VERSION "created by canmatrix"

NS_ :

BS_:

BU_: User ADB_PC_AC01 ADB_PC_BASE ADB_PC_BOX

BO_ 2155937856 AC01_Mode_Set: 1 User
 SG_ mode : 0|8@1+ (1,0) [0|255] "" ADB_PC_AC01,User

BO_ 2155937857 AC01_Mode_Applied: 1 ADB_PC_AC01
 SG_ mode : 0|8@1+ (1,0) [0|255] "" User

BO_ 2155937858 AC01_faults: 8 ADB_PC_AC01
 SG_ CABLE_1_2_L1 : 0|1@1+ (1,0) [0|1] "" User
 SG_ CABLE_1_3_L1 : 1|1@1+ (1,0) [0|1] "" User
 SG_ CABLE_1_2_L2 : 2|1@1+ (1,0) [0|1] "" User
 SG_ CABLE_1_3_L2 : 3|1@1+ (1,0) [0|1] "" User
 SG_ CABLE_1_2_L3 : 4|1@1+ (1,0) [0|1] "" User
 SG_ CABLE_1_3_L3 : 5|1@1+ (1,0) [0|1] "" User
 SG_ CABLE_4_5_L1 : 6|1@1+ (1,0) [0|1] "" User
 SG_ CABLE_4_6_L1 : 7|1@1+ (1,0) [0|1] "" User
 SG_ CABLE_4_5_L2 : 8|1@1+ (1,0) [0|1] "" User
 SG_ CABLE_4_6_L2 : 9|1@1+ (1,0) [0|1] "" User
 SG_ CABLE_4_5_L3 : 10|1@1+ (1,0) [0|1] "" User
 SG_ CABLE_4_6_L3 : 11|1@1+ (1,0) [0|1] "" User
 SG_ CABLE_1_4_L1 : 12|1@1+ (1,0) [0|1] "" User
 SG_ CABLE_1_4_L2 : 13|1@1+ (1,0) [0|1] "" User
 SG_ CABLE_1_4_L3 : 14|1@1+ (1,0) [0|1] "" User
 SG_ CABLE_2_3_DC : 15|1@1+ (1,0) [0|1] "" User
 SG_ CABLE_5_6_DC : 16|1@1+ (1,0) [0|1] "" User
 SG_ CABLE_3_5_DC : 17|1@1+ (1,0) [0|1] "" User
 SG_ MODULE_1_RUNNING : 18|1@1+ (1,0) [0|1] "" User
 SG_ MODULE_2_RUNNING : 19|1@1+ (1,0) [0|1] "" User
 SG_ MODULE_3_RUNNING : 20|1@1+ (1,0) [0|1] "" User
 SG_ MODULE_4_RUNNING : 21|1@1+ (1,0) [0|1] "" User
 SG_ MODULE_5_RUNNING : 22|1@1+ (1,0) [0|1] "" User
 SG_ MODULE_6_RUNNING : 23|1@1+ (1,0) [0|1] "" User
 SG_ reserved_1 : 24|1@1+ (1,0) [0|1] "" User
 SG_ reserved_2 : 25|1@1+ (1,0) [0|1] "" User
 SG_ reserved_3 : 26|1@1+ (1,0) [0|1] "" User
 SG_ reserved_4 : 27|1@1+ (1,0) [0|1] "" User
 SG_ PRECHARGE_FAILED : 28|1@1+ (1,0) [0|1] "" User
 SG_ Main_Contactors_failed : 29|1@1+ (1,0) [0|1] "" User
 SG_ FILTER_NOT_RUNNING : 30|1@1+ (1,0) [0|1] "" User
 SG_ RECTIFIER_3P_NOT_RUNNING : 31|1@1+ (1,0) [0|1] "" User
 SG_ AFE_NOT_OFF : 32|1@1+ (1,0) [0|1] "" User
 SG_ FILTER_STOP_RUNNING : 34|1@1+ (1,0) [0|1] "" User
 SG_ RECTIFIER_3P_STOP_RUNNING : 35|1@1+ (1,0) [0|1] "" User
 SG_ AFE_PWM_NOT_RUNNING : 36|1@1+ (1,0) [0|1] "" User
 SG_ AFE_PWM_STOP_RUNNING : 37|1@1+ (1,0) [0|1] "" User
 SG_ BLEEDING_FAILED : 38|1@1+ (1,0) [0|1] "" User
 SG_ FILTER_NOT_OFF : 39|1@1+ (1,0) [0|1] "" User
 SG_ INVERTER_3P_NOT_RUNNING : 40|1@1+ (1,0) [0|1] "" User
 SG_ INVERTER_3P_STOP_RUNNING : 41|1@1+ (1,0) [0|1] "" User

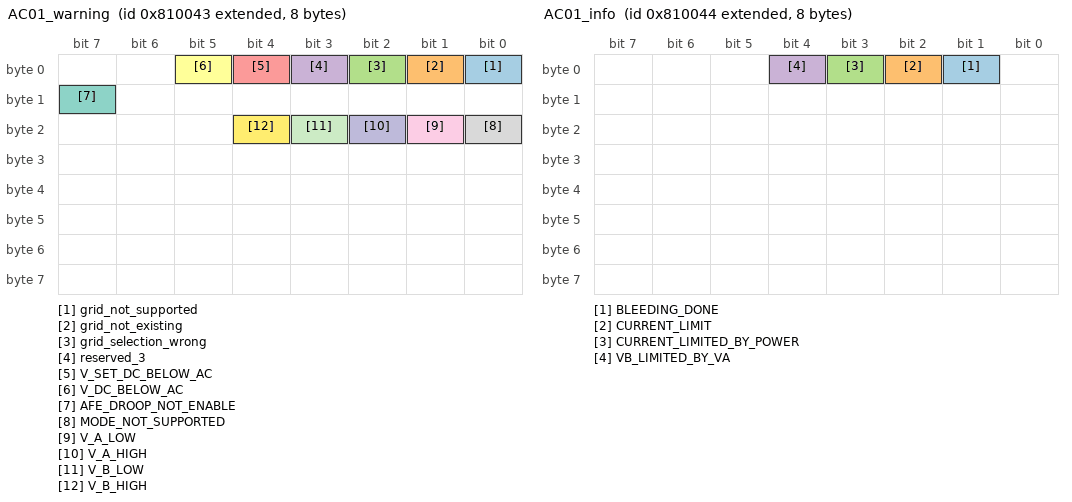
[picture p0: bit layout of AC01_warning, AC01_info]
BO_ 2155937859 AC01_warning: 8 ADB_PC_AC01
 SG_ grid_not_supported : 0|1@1+ (1,0) [0|1] "" User
 SG_ grid_not_existing : 1|1@1+ (1,0) [0|1] "" User
 SG_ grid_selection_wrong : 2|1@1+ (1,0) [0|1] "" User
 SG_ reserved_3 : 3|1@1+ (1,0) [0|1] "" User
 SG_ V_SET_DC_BELOW_AC : 4|1@1+ (1,0) [0|1] "" User
 SG_ V_DC_BELOW_AC : 5|1@1+ (1,0) [0|1] "" User
 SG_ AFE_DROOP_NOT_ENABLE : 15|1@1+ (1,0) [0|1] "" User
 SG_ MODE_NOT_SUPPORTED : 16|1@1+ (1,0) [0|1] "" User
 SG_ V_A_LOW : 17|1@1+ (1,0) [0|1] "" User
 SG_ V_A_HIGH : 18|1@1+ (1,0) [0|1] "" User
 SG_ V_B_LOW : 19|1@1+ (1,0) [0|1] "" User
 SG_ V_B_HIGH : 20|1@1+ (1,0) [0|1] "" User

BO_ 2155937860 AC01_info: 8 ADB_PC_AC01
 SG_ BLEEDING_DONE : 1|1@1+ (1,0) [0|1] "" User
 SG_ CURRENT_LIMIT : 2|1@1+ (1,0) [0|1] "" User
 SG_ CURRENT_LIMITED_BY_POWER : 3|1@1+ (1,0) [0|1] "" User
 SG_ VB_LIMITED_BY_VA : 4|1@1+ (1,0) [0|1] "" User

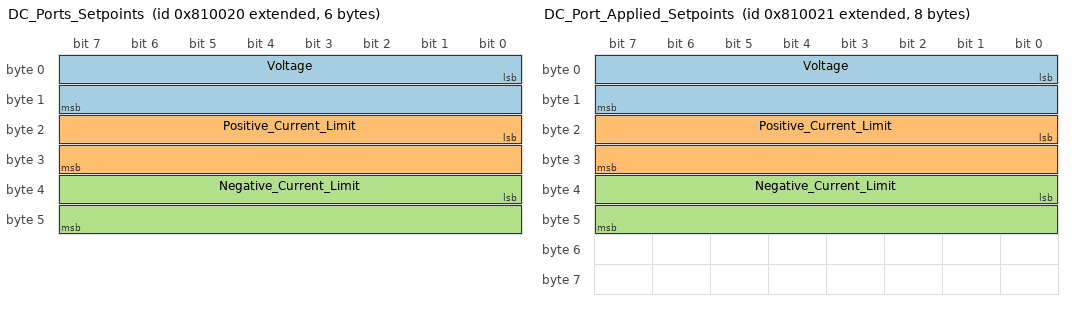
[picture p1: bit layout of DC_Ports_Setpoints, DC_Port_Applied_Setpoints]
BO_ 2155937824 DC_Ports_Setpoints: 6 User
 SG_ Voltage : 0|16@1+ (0.1,0) [0|6553.5] "V" ADB_PC_AC01,User
 SG_ Positive_Current_Limit : 16|16@1- (0.1,0) [-3276.8|3276.7] "A" ADB_PC_AC01,User
 SG_ Negative_Current_Limit : 32|16@1- (0.1,0) [-3276.8|3276.7] "A" ADB_PC_AC01,User

BO_ 2155937825 DC_Port_Applied_Setpoints: 8 ADB_PC_AC01
 SG_ Voltage : 0|16@1+ (0.1,0) [0|6553.5] "V" User
 SG_ Positive_Current_Limit : 16|16@1- (0.1,0) [-3276.8|3276.7] "A" User
 SG_ Negative_Current_Limit : 32|16@1- (0.1,0) [-3276.8|3276.7] "A" User

BO_ 2155937828 DC_Port_Measurements: 4 ADB_PC_AC01
 SG_ Voltage : 0|16@1+ (0.1,0) [0|6553.5] "V" User
 SG_ Current : 16|16@1- (0.1,0) [-3276.8|3276.7] "A" User

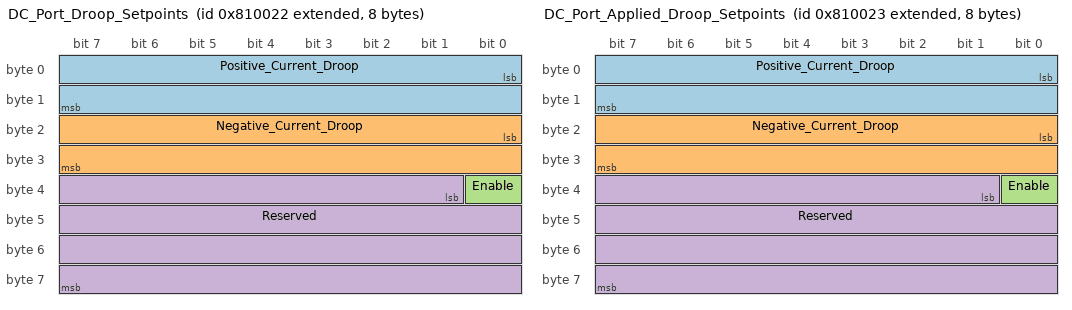
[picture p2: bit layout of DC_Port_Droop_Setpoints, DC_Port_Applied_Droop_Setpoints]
BO_ 2155937826 DC_Port_Droop_Setpoints: 8 User
 SG_ Positive_Current_Droop : 0|16@1+ (0.01,0) [0.00|655.35] "Ohm" ADB_PC_AC01,User
 SG_ Negative_Current_Droop : 16|16@1+ (0.01,0) [0.00|655.35] "Ohm" ADB_PC_AC01,User
 SG_ Enable : 32|1@1+ (1,0) [0|1] "" ADB_PC_AC01,User,ADB_PC_BOX
 SG_ Reserved : 33|31@1+ (1,0) [0|2147483647] "" ADB_PC_AC01,User,ADB_PC_BASE

BO_ 2155937827 DC_Port_Applied_Droop_Setpoints: 8 ADB_PC_AC01
 SG_ Positive_Current_Droop : 0|16@1+ (0.01,0) [0.00|655.35] "Ohm" User
 SG_ Negative_Current_Droop : 16|16@1+ (0.01,0) [0.00|655.35] "Ohm" User
 SG_ Enable : 32|1@1+ (1,0) [0|1] "" User
 SG_ Reserved : 33|31@1+ (1,0) [0|2147483647] "" User

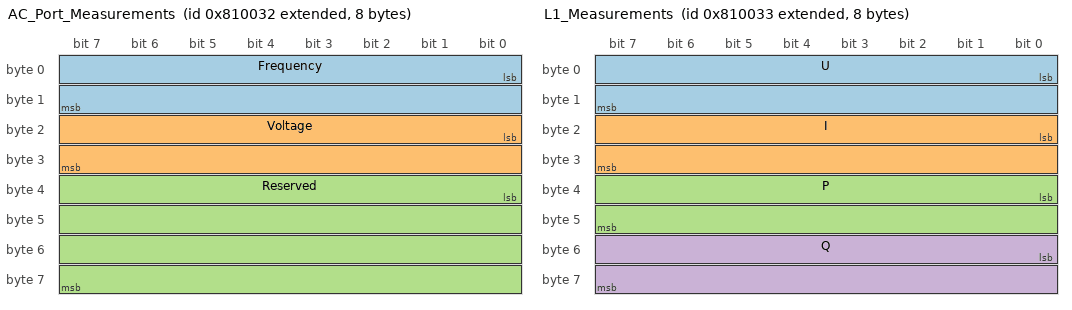
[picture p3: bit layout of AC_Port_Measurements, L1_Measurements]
BO_ 2155937842 AC_Port_Measurements: 8 ADB_PC_AC01
 SG_ Frequency : 0|16@1+ (0.01,0) [0.00|655.35] "Hz" User
 SG_ Voltage : 16|16@1+ (0.1,0) [0|6553.5] "V" User
 SG_ Reserved : 32|32@1+ (1,0) [0|4294967295] "" User

BO_ 2155937843 L1_Measurements: 8 ADB_PC_AC01
 SG_ U : 0|16@1- (0.1,0) [-3276.8|3276.7] "V" User
 SG_ I : 16|16@1- (0.1,0) [-3276.8|3276.7] "A" User
 SG_ P : 32|16@1- (0.1,0) [-3276.8|3276.7] "W" User
 SG_ Q : 48|16@1- (0.1,0) [-3276.8|3276.7] "VAR" User,ADB_PC_AC01

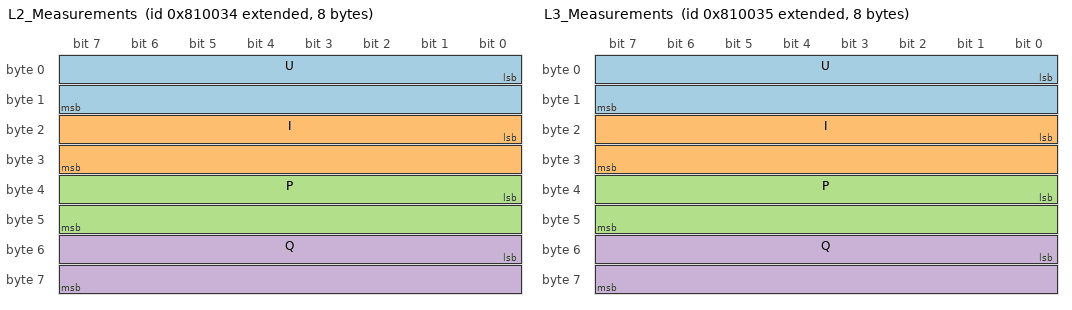
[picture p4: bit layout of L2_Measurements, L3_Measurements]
BO_ 2155937844 L2_Measurements: 8 ADB_PC_AC01
 SG_ U : 0|16@1- (0.1,0) [-3276.8|3276.7] "V" User
 SG_ I : 16|16@1- (0.1,0) [-3276.8|3276.7] "A" User
 SG_ P : 32|16@1- (0.1,0) [-3276.8|3276.7] "W" User
 SG_ Q : 48|16@1- (0.1,0) [-3276.8|3276.7] "VAR" User

BO_ 2155937845 L3_Measurements: 8 ADB_PC_AC01
 SG_ U : 0|16@1- (0.1,0) [-3276.8|3276.7] "V" User
 SG_ I : 16|16@1- (0.1,0) [-3276.8|3276.7] "A" User
 SG_ P : 32|16@1- (0.1,0) [-3276.8|3276.7] "W" User
 SG_ Q : 48|16@1- (0.1,0) [-3276.8|3276.7] "VAR" User

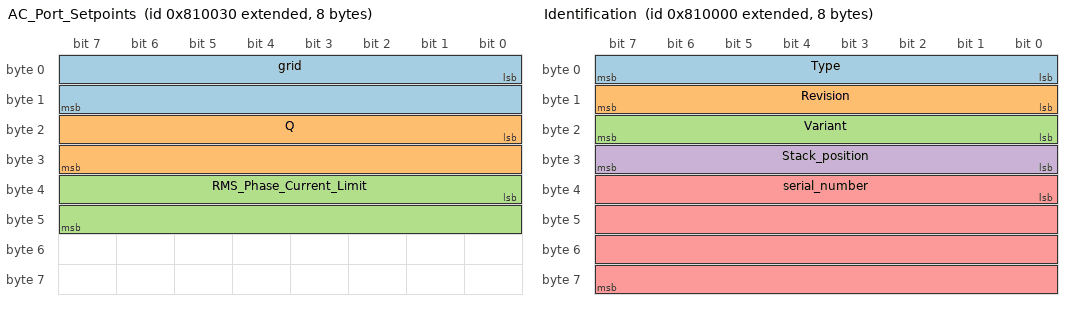
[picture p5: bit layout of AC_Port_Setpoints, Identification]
BO_ 2155937840 AC_Port_Setpoints: 8 User
 SG_ grid : 0|16@1+ (1,0) [0|65535] "" ADB_PC_AC01,User
 SG_ Q : 16|16@1- (10,0) [-327680|327670] "VAR" ADB_PC_AC01
 SG_ RMS_Phase_Current_Limit : 32|16@1+ (0.1,0) [0|6553.5] "A" ADB_PC_AC01,User

BO_ 2155937841 AC_Port_Applied_Setpoints: 8 ADB_PC_AC01
 SG_ grid : 0|16@1+ (1,0) [0|65535] "" User
 SG_ Q : 16|16@1- (10,0) [-327680|327670] "VAR" User
 SG_ RMS_Phase_Current_Limit : 32|16@1+ (0.1,0) [0|6553.5] "A" User

BO_ 2155937792 Identification: 8 ADB_PC_BASE
 SG_ Type : 0|8@1+ (1,0) [0|255] "" User
 SG_ Revision : 8|8@1+ (1,0) [0|255] "" User
 SG_ Variant : 16|8@1+ (1,0) [0|255] "" User
 SG_ Stack_position : 24|8@1+ (1,0) [0|255] "" User,ADB_PC_BASE
 SG_ serial_number : 32|32@1+ (1,0) [0|4294967295] "" User

BO_ 2155937794 Firmware_UID: 8 ADB_PC_BASE
 SG_ UID : 0|64@1+ (1,0) [0|1.844674407370955E+019] "" User

BO_ 2155937793 Bootloader_UID: 8 ADB_PC_BASE
 SG_ UID : 0|64@1+ (1,0) [0|1.844674407370955E+019] "" User

BO_ 2155937795 ADB_CAN_API_Version: 3 ADB_PC_BASE
 SG_ Major : 0|8@1+ (1,0) [0|255] "" User
 SG_ Minor : 8|8@1+ (1,0) [0|255] "" User
 SG_ Patch : 16|8@1+ (1,0) [0|255] "" User

BO_ 2155937861 Stack_Control: 6 User
 SG_ Stack_position : 0|8@1+ (1,0) [0|255] "" ADB_PC_BASE
 SG_ reserved : 8|8@1+ (1,0) [0|255] "" ADB_PC_BASE,User
 SG_ SN_number : 16|32@1+ (1,0) [0|4294967295] "" ADB_PC_BASE

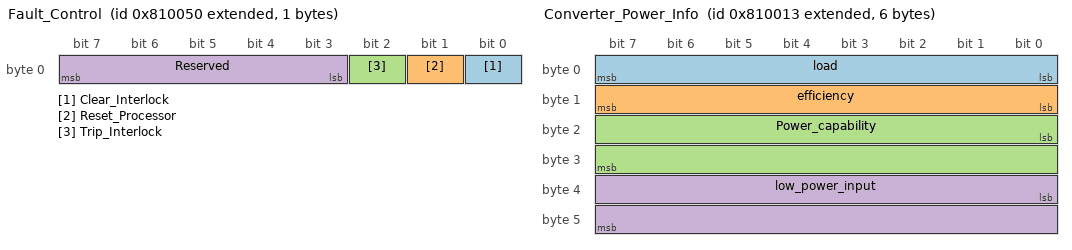
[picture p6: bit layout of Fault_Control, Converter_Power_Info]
BO_ 2155937872 Fault_Control: 1 User
 SG_ Clear_Interlock : 0|1@1+ (1,0) [0|1] "" ADB_PC_BASE
 SG_ Reset_Processor : 1|1@1+ (1,0) [0|1] "" ADB_PC_BASE
 SG_ Trip_Interlock : 2|1@1+ (1,0) [0|1] "" ADB_PC_BASE
 SG_ Reserved : 3|5@1+ (1,0) [0|31] "" ADB_PC_BASE

BO_ 2155937889 Factory_Control: 8 User
 SG_ Factory_mode : 0|1@1+ (1,0) [0|1] "" ADB_PC_BASE

BO_ 2155937810 Converter_Control: 1 User
 SG_ enable : 0|1@1+ (1,0) [0|1] "" ADB_PC_BOX
 SG_ sleep : 1|1@1+ (1,0) [0|1] "" ADB_PC_BOX

BO_ 2155937811 Converter_Power_Info: 6 ADB_PC_BOX
 SG_ load : 0|8@1+ (1,0) [0|255] "%" User
 SG_ efficiency : 8|8@1+ (1,0) [0|255] "%" User
 SG_ Power_capability : 16|16@1- (0.1,0) [-3276.8|3276.7] "kw" User
 SG_ low_power_input : 32|16@1- (0.01,0) [-327.68|327.67] "v" User

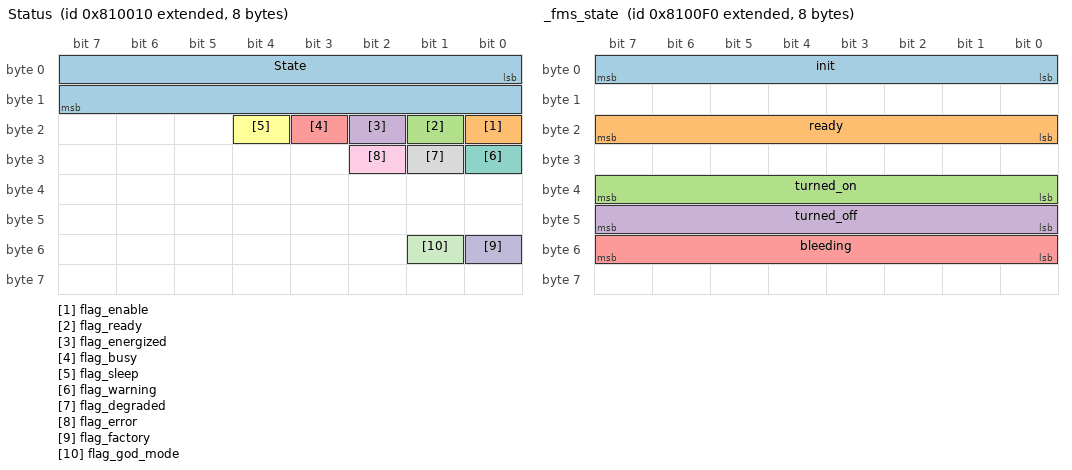
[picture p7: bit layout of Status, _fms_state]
BO_ 2155937808 Status: 8 ADB_PC_BOX
 SG_ State : 0|16@1+ (1,0) [0|65535] "" User
 SG_ flag_enable : 16|1@1+ (1,0) [0|1] "" User
 SG_ flag_ready : 17|1@1+ (1,0) [0|1] "" User
 SG_ flag_energized : 18|1@1+ (1,0) [0|1] "" User
 SG_ flag_busy : 19|1@1+ (1,0) [0|1] "" User
 SG_ flag_sleep : 20|1@1+ (1,0) [0|1] "" User
 SG_ flag_warning : 24|1@1+ (1,0) [0|1] "" User
 SG_ flag_degraded : 25|1@1+ (1,0) [0|1] "" User
 SG_ flag_error : 26|1@1+ (1,0) [0|1] "" User
 SG_ flag_factory : 48|1@1+ (1,0) [0|1] "" User
 SG_ flag_god_mode : 49|1@1+ (1,0) [0|1] "" User

BO_ 2155938032 _fms_state: 8 ADB_PC_BOX
 SG_ init : 0|8@1+ (1,0) [0|255] "" User
 SG_ ready : 16|8@1+ (1,0) [0|255] "" User
 SG_ turned_on : 32|8@1+ (1,0) [0|255] "" User
 SG_ turned_off : 40|8@1+ (1,0) [0|255] "" User
 SG_ bleeding : 48|8@1+ (1,0) [0|255] "" User

BO_ 2155937809 Faults: 8 ADB_PC_BOX
 SG_ internal : 0|1@1+ (1,0) [0|1] "" User
 SG_ external : 1|1@1+ (1,0) [0|1] "" User
 SG_ system : 2|1@1+ (1,0) [0|1] "" User
 SG_ EEPROM_failure : 3|1@1+ (1,0) [0|1] "" User
 SG_ wrong_nfo : 4|1@1+ (1,0) [0|1] "" User
 SG_ Measurement_system_failure : 5|1@1+ (1,0) [0|1] "" User
 SG_ PLL_not_locked : 6|1@1+ (1,0) [0|1] "" User
 SG_ overtemperature : 7|1@1+ (1,0) [0|1] "" User
 SG_ fan_stuck : 8|1@1+ (1,0) [0|1] "" User
 SG_ dead_module : 9|1@1+ (1,0) [0|1] "" User
 SG_ keep_alive_not_serv_internal : 10|1@1+ (1,0) [0|1] "" User
 SG_ error_temperature : 11|1@1+ (1,0) [0|1] "" User
 SG_ internal_modules_ready : 12|1@1+ (1,0) [0|1] "" User
 SG_ internal_modules_can_api : 13|1@1+ (1,0) [0|1] "" User
 SG_ internal_modules_missing : 14|1@1+ (1,0) [0|1] "" User
 SG_ internal_modules_wrong : 15|1@1+ (1,0) [0|1] "" User
 SG_ internal_modules_stack : 16|1@1+ (1,0) [0|1] "" User
 SG_ internal_modules_init : 17|1@1+ (1,0) [0|1] "" User
 SG_ wrong_revision : 18|1@1+ (1,0) [0|1] "" User
 SG_ v_in_low : 19|1@1+ (1,0) [0|1] "" User
 SG_ v_in_critical : 20|1@1+ (1,0) [0|1] "" User
 SG_ keep_alive_not_serv : 21|1@1+ (1,0) [0|1] "" User

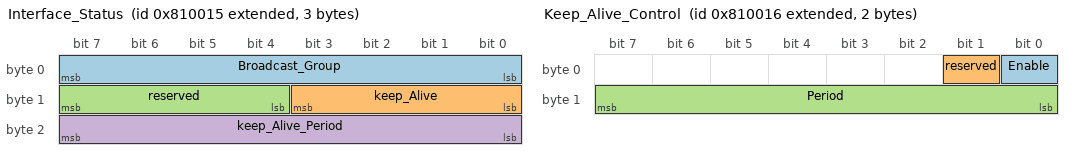
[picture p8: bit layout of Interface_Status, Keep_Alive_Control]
BO_ 2155937813 Interface_Status: 3 ADB_PC_BOX
 SG_ Broadcast_Group : 0|8@1+ (1,0) [0|30] "" User
 SG_ keep_Alive : 8|4@1+ (1,0) [0|15] "" User
 SG_ reserved : 12|4@1+ (1,0) [0|15] "" User
 SG_ keep_Alive_Period : 16|8@1+ (0.1,0) [0|25.5] "s" User

BO_ 2155937814 Keep_Alive_Control: 2 User
 SG_ Enable : 0|1@1+ (1,0) [0|1] "" ADB_PC_BOX
 SG_ reserved : 1|1@1+ (1,0) [0|1] "" User
 SG_ Period : 8|8@1+ (0.1,0) [0|25.5] "s" User

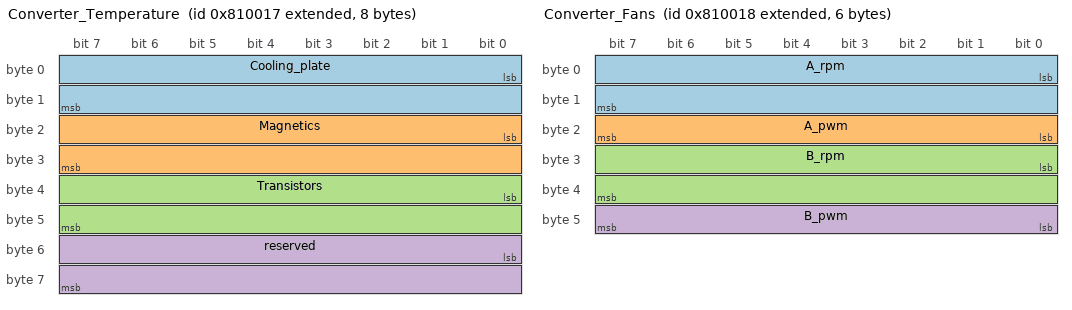
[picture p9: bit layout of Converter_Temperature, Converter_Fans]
BO_ 2155937815 Converter_Temperature: 8 ADB_PC_BOX
 SG_ Cooling_plate : 0|16@1- (0.01,0) [-327.68|327.67] "°C" User
 SG_ Magnetics : 16|16@1- (0.01,0) [-327.68|327.67] "°C" User
 SG_ Transistors : 32|16@1- (0.01,0) [-327.68|327.67] "°C" User
 SG_ reserved : 48|16@1- (0.01,0) [-327.68|327.67] "°C" User

BO_ 2155937816 Converter_Fans: 6 ADB_PC_BOX
 SG_ A_rpm : 0|16@1+ (1,0) [0|65535] "rpm" User
 SG_ A_pwm : 16|8@1+ (1,0) [0|255] "%" User
 SG_ B_rpm : 24|16@1+ (1,0) [0|65535] "rpm" User
 SG_ B_pwm : 40|8@1+ (1,0) [0|255] "%" User

BO_ 2155937817 Keep_Alive_Feed: 1 User
 SG_ feed : 0|1@1+ (1,0) [0|1] "" ADB_PC_BOX

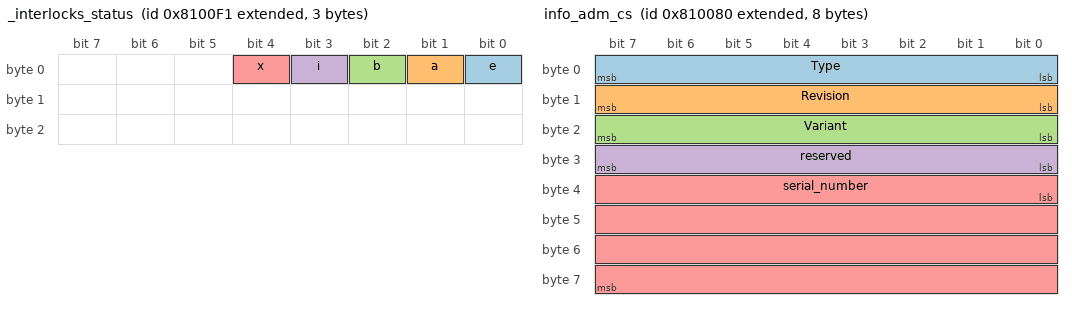
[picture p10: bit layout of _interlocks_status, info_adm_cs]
BO_ 2155938033 _interlocks_status: 3 ADB_PC_BOX
 SG_ e : 0|1@1+ (1,0) [0|1] "" User
 SG_ a : 1|1@1+ (1,0) [0|1] "" User
 SG_ b : 2|1@1+ (1,0) [0|1] "" User
 SG_ i : 3|1@1+ (1,0) [0|1] "" User
 SG_ x : 4|1@1+ (1,0) [0|1] "" User

BO_ 2155937812 Broadcast_Group_Control: 1 User
 SG_ Group_ID : 0|8@1+ (1,0) [0|255] "" ADB_PC_BOX

BO_ 2155937920 info_adm_cs: 8 ADB_PC_BOX
 SG_ Type : 0|8@1+ (1,0) [0|255] "" User
 SG_ Revision : 8|8@1+ (1,0) [0|255] "" User
 SG_ Variant : 16|8@1+ (1,0) [0|255] "" User
 SG_ reserved : 24|8@1+ (1,0) [0|255] "" User
 SG_ serial_number : 32|32@1+ (1,0) [0|4294967295] "" User

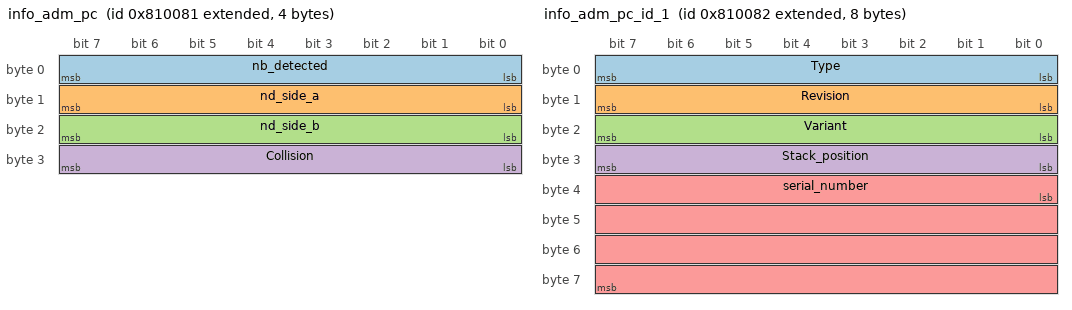
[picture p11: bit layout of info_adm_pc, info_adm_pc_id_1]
BO_ 2155937921 info_adm_pc: 4 ADB_PC_BOX
 SG_ nb_detected : 0|8@1+ (1,0) [0|255] "" User
 SG_ nd_side_a : 8|8@1+ (1,0) [0|255] "" User
 SG_ nd_side_b : 16|8@1+ (1,0) [0|255] "" User
 SG_ Collision : 24|8@1+ (1,0) [0|255] "" User

BO_ 2155937922 info_adm_pc_id_1: 8 ADB_PC_BOX
 SG_ Type : 0|8@1+ (1,0) [0|255] "" User
 SG_ Revision : 8|8@1+ (1,0) [0|255] "" User
 SG_ Variant : 16|8@1+ (1,0) [0|255] "" User
 SG_ Stack_position : 24|8@1+ (1,0) [0|255] "" User
 SG_ serial_number : 32|32@1+ (1,0) [0|4294967295] "" User

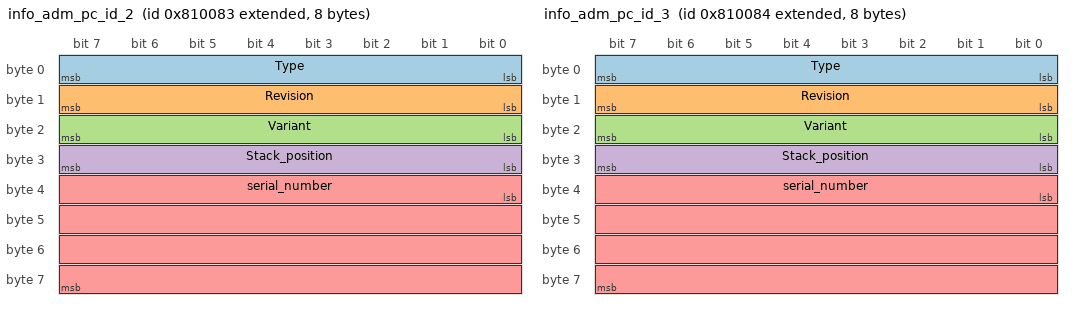
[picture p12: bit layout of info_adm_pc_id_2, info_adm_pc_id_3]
BO_ 2155937923 info_adm_pc_id_2: 8 ADB_PC_BOX
 SG_ Type : 0|8@1+ (1,0) [0|255] "" User
 SG_ Revision : 8|8@1+ (1,0) [0|255] "" User
 SG_ Variant : 16|8@1+ (1,0) [0|255] "" User
 SG_ Stack_position : 24|8@1+ (1,0) [0|255] "" User
 SG_ serial_number : 32|32@1+ (1,0) [0|4294967295] "" User

BO_ 2155937924 info_adm_pc_id_3: 8 ADB_PC_BOX
 SG_ Type : 0|8@1+ (1,0) [0|255] "" User
 SG_ Revision : 8|8@1+ (1,0) [0|255] "" User
 SG_ Variant : 16|8@1+ (1,0) [0|255] "" User
 SG_ Stack_position : 24|8@1+ (1,0) [0|255] "" User
 SG_ serial_number : 32|32@1+ (1,0) [0|4294967295] "" User

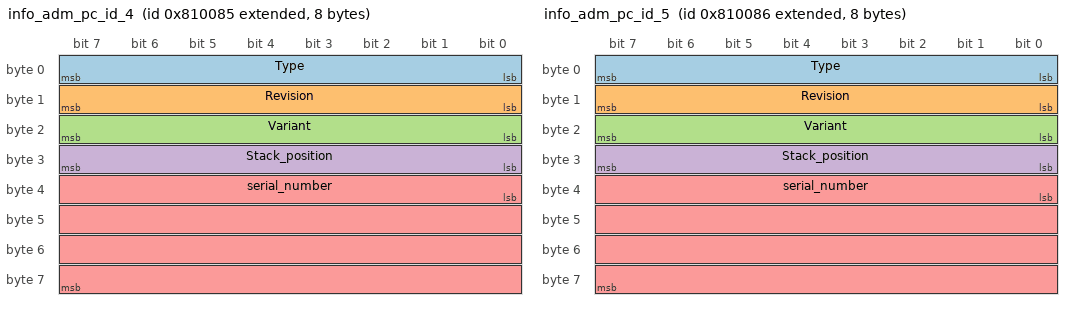
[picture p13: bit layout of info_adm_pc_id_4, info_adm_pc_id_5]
BO_ 2155937925 info_adm_pc_id_4: 8 ADB_PC_BOX
 SG_ Type : 0|8@1+ (1,0) [0|255] "" User
 SG_ Revision : 8|8@1+ (1,0) [0|255] "" User
 SG_ Variant : 16|8@1+ (1,0) [0|255] "" User
 SG_ Stack_position : 24|8@1+ (1,0) [0|255] "" User
 SG_ serial_number : 32|32@1+ (1,0) [0|4294967295] "" User

BO_ 2155937926 info_adm_pc_id_5: 8 ADB_PC_BOX
 SG_ Type : 0|8@1+ (1,0) [0|255] "" User
 SG_ Revision : 8|8@1+ (1,0) [0|255] "" User
 SG_ Variant : 16|8@1+ (1,0) [0|255] "" User
 SG_ Stack_position : 24|8@1+ (1,0) [0|255] "" User
 SG_ serial_number : 32|32@1+ (1,0) [0|4294967295] "" User

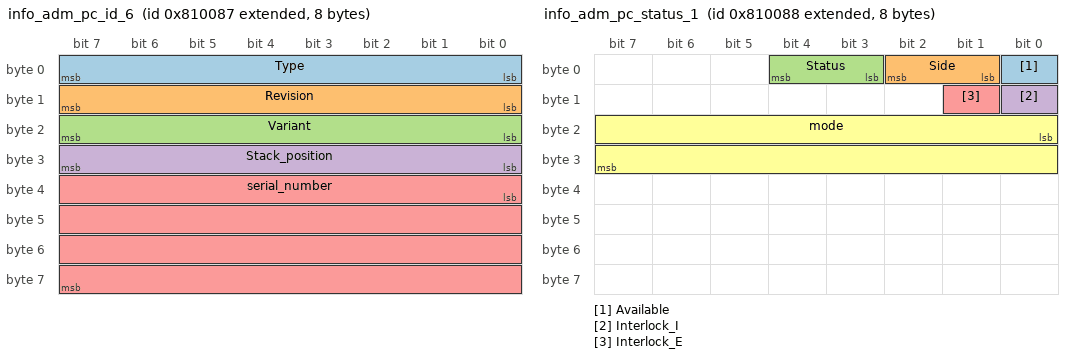
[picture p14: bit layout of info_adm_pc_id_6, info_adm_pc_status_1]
BO_ 2155937927 info_adm_pc_id_6: 8 ADB_PC_BOX
 SG_ Type : 0|8@1+ (1,0) [0|255] "" User
 SG_ Revision : 8|8@1+ (1,0) [0|255] "" User
 SG_ Variant : 16|8@1+ (1,0) [0|255] "" User
 SG_ Stack_position : 24|8@1+ (1,0) [0|255] "" User
 SG_ serial_number : 32|32@1+ (1,0) [0|4294967295] "" User

BO_ 2155937928 info_adm_pc_status_1: 8 ADB_PC_BOX
 SG_ Available : 0|1@1+ (1,0) [0|1] "" User
 SG_ Side : 1|2@1+ (1,0) [0|3] "" User
 SG_ Status : 3|2@1+ (1,0) [0|3] "" User
 SG_ Interlock_I : 8|1@1+ (1,0) [0|1] "" User
 SG_ Interlock_E : 9|1@1+ (1,0) [0|1] "" User
 SG_ mode : 16|16@1+ (1,0) [0|65535] "" User

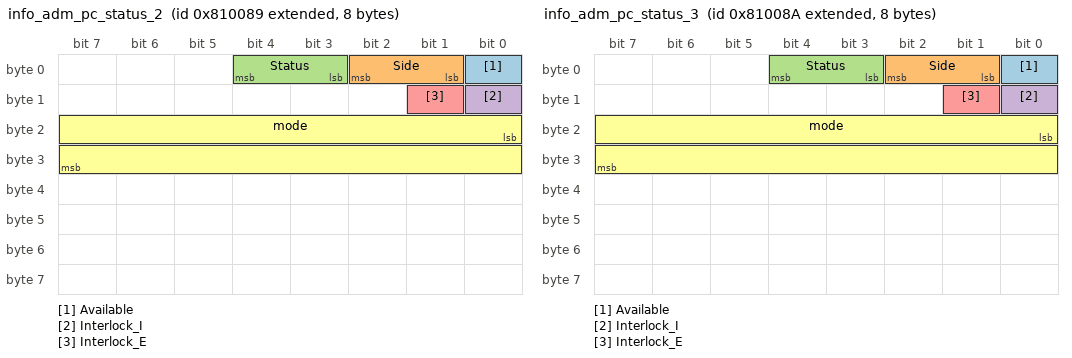
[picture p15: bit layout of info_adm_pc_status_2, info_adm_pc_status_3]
BO_ 2155937929 info_adm_pc_status_2: 8 ADB_PC_BOX
 SG_ Available : 0|1@1+ (1,0) [0|1] "" User
 SG_ Side : 1|2@1+ (1,0) [0|3] "" User
 SG_ Status : 3|2@1+ (1,0) [0|3] "" User
 SG_ Interlock_I : 8|1@1+ (1,0) [0|1] "" User
 SG_ Interlock_E : 9|1@1+ (1,0) [0|1] "" User
 SG_ mode : 16|16@1+ (1,0) [0|65535] "" User

BO_ 2155937930 info_adm_pc_status_3: 8 ADB_PC_BOX
 SG_ Available : 0|1@1+ (1,0) [0|1] "" User
 SG_ Side : 1|2@1+ (1,0) [0|3] "" User
 SG_ Status : 3|2@1+ (1,0) [0|3] "" User
 SG_ Interlock_I : 8|1@1+ (1,0) [0|1] "" User
 SG_ Interlock_E : 9|1@1+ (1,0) [0|1] "" User
 SG_ mode : 16|16@1+ (1,0) [0|65535] "" User

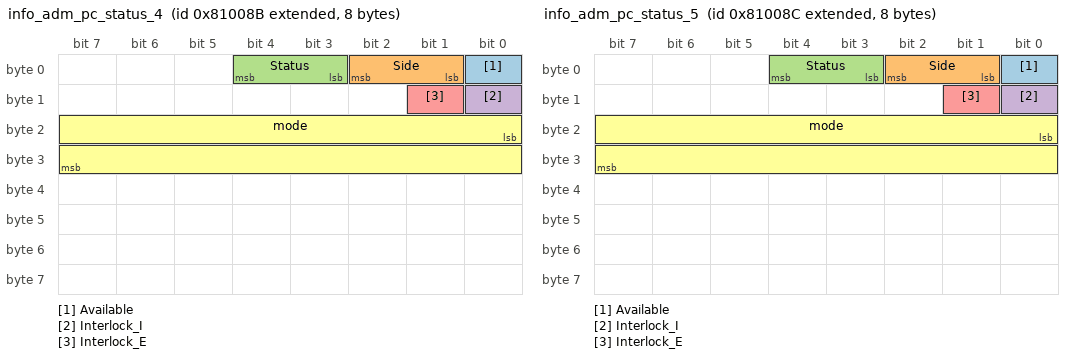
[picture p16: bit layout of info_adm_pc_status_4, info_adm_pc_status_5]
BO_ 2155937931 info_adm_pc_status_4: 8 ADB_PC_BOX
 SG_ Available : 0|1@1+ (1,0) [0|1] "" User
 SG_ Side : 1|2@1+ (1,0) [0|3] "" User
 SG_ Status : 3|2@1+ (1,0) [0|3] "" User
 SG_ Interlock_I : 8|1@1+ (1,0) [0|1] "" User
 SG_ Interlock_E : 9|1@1+ (1,0) [0|1] "" User
 SG_ mode : 16|16@1+ (1,0) [0|65535] "" User

BO_ 2155937932 info_adm_pc_status_5: 8 ADB_PC_BOX
 SG_ Available : 0|1@1+ (1,0) [0|1] "" User
 SG_ Side : 1|2@1+ (1,0) [0|3] "" User
 SG_ Status : 3|2@1+ (1,0) [0|3] "" User
 SG_ Interlock_I : 8|1@1+ (1,0) [0|1] "" User
 SG_ Interlock_E : 9|1@1+ (1,0) [0|1] "" User
 SG_ mode : 16|16@1+ (1,0) [0|65535] "" User

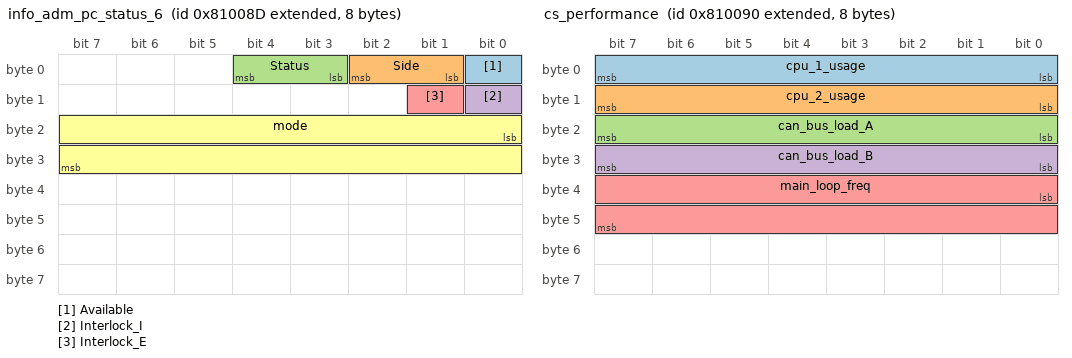
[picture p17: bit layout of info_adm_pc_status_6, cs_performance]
BO_ 2155937933 info_adm_pc_status_6: 8 ADB_PC_BOX
 SG_ Available : 0|1@1+ (1,0) [0|1] "" User
 SG_ Side : 1|2@1+ (1,0) [0|3] "" User
 SG_ Status : 3|2@1+ (1,0) [0|3] "" User
 SG_ Interlock_I : 8|1@1+ (1,0) [0|1] "" User
 SG_ Interlock_E : 9|1@1+ (1,0) [0|1] "" User
 SG_ mode : 16|16@1+ (1,0) [0|65535] "" User

BO_ 2155937936 cs_performance: 8 ADB_PC_BOX
 SG_ cpu_1_usage : 0|8@1+ (1,0) [0|255] "%" User
 SG_ cpu_2_usage : 8|8@1+ (1,0) [0|255] "%" User
 SG_ can_bus_load_A : 16|8@1+ (1,0) [0|255] "%" User
 SG_ can_bus_load_B : 24|8@1+ (1,0) [0|255] "%" User
 SG_ main_loop_freq : 32|16@1+ (1,0) [0|65535] "Hz" User

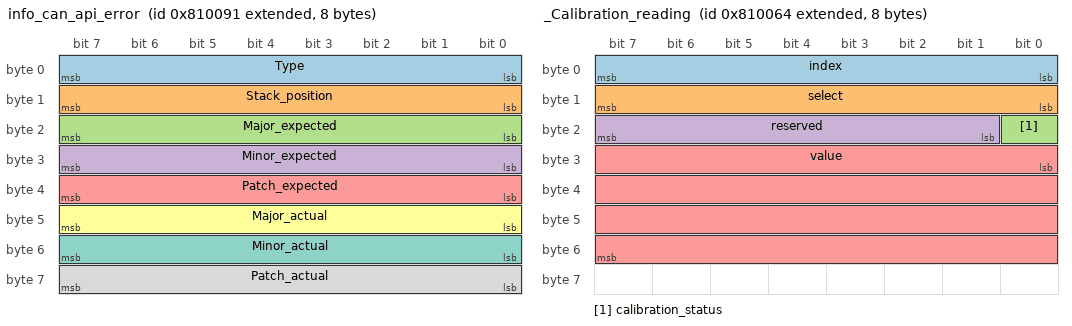
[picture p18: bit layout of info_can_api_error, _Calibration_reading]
BO_ 2155937937 info_can_api_error: 8 ADB_PC_BOX
 SG_ Type : 0|8@1+ (1,0) [0|255] "" User
 SG_ Stack_position : 8|8@1+ (1,0) [0|255] "" User
 SG_ Major_expected : 16|8@1+ (1,0) [0|255] "" User
 SG_ Minor_expected : 24|8@1+ (1,0) [0|255] "" User
 SG_ Patch_expected : 32|8@1+ (1,0) [0|255] "" User
 SG_ Major_actual : 40|8@1+ (1,0) [0|255] "" User
 SG_ Minor_actual : 48|8@1+ (1,0) [0|255] "" User
 SG_ Patch_actual : 56|8@1+ (1,0) [0|255] "" User

BO_ 2155937890 _Calibration_writing: 6 User
 SG_ index : 0|8@1+ (1,0) [0|255] "" ADB_PC_BOX,User
 SG_ select : 8|8@1+ (1,0) [0|255] "" ADB_PC_BOX,User
 SG_ value : 16|32@1- (0.0001,0) [-214748.3648|214748.3647] "" ADB_PC_BOX,User

BO_ 2155937891 _Calibration_reading_cmd: 2 User
 SG_ index : 0|8@1+ (1,0) [0|255] "" ADB_PC_BOX
 SG_ select : 8|8@1+ (1,0) [0|255] "" ADB_PC_BOX

BO_ 2155937892 _Calibration_reading: 8 ADB_PC_BOX
 SG_ index : 0|8@1+ (1,0) [0|255] "" User
 SG_ select : 8|8@1+ (1,0) [0|255] "" User
 SG_ calibration_status : 16|1@1+ (1,0) [0|1] "" User
 SG_ reserved : 17|7@1+ (1,0) [0|127] "" User
 SG_ value : 24|32@1- (0.0001,0) [-214748.3648|214748.3647] "" User

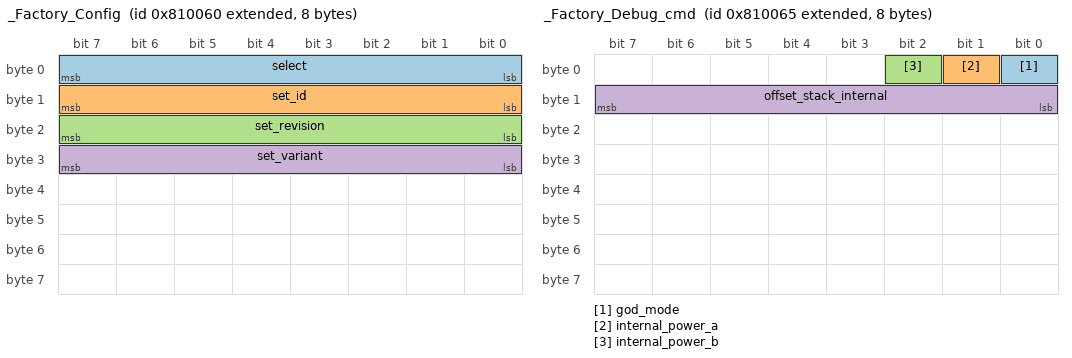
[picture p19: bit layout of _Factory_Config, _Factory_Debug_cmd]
BO_ 2155937888 _Factory_Config: 8 User
 SG_ select : 0|8@1+ (1,0) [0|255] "" ADB_PC_BOX
 SG_ set_id : 8|8@1+ (1,0) [0|255] "" ADB_PC_BOX
 SG_ set_revision : 16|8@1+ (1,0) [0|255] "" ADB_PC_BOX
 SG_ set_variant : 24|8@1+ (1,0) [0|255] "" ADB_PC_BOX

BO_ 2155937893 _Factory_Debug_cmd: 8 User
 SG_ god_mode : 0|1@1+ (1,0) [0|1] "" ADB_PC_BOX
 SG_ internal_power_a : 1|1@1+ (1,0) [0|1] "" ADB_PC_BOX
 SG_ internal_power_b : 2|1@1+ (1,0) [0|1] "" ADB_PC_BOX
 SG_ offset_stack_internal : 8|8@1+ (1,0) [0|255] "offset" ADB_PC_BOX

CM_ BO_ 2155937856  "Configure AC01 operating mode";
CM_ BO_ 2155937857  "AC01 actual operating mode (readback)";
CM_ BO_ 2155937858  "AC01 Critical and error conditions";
CM_ BO_ 2155937859  "AC01 warning flags, it need to be cleared to \"Enable\" the power converter";
CM_ BO_ 2155937860  "Info: Informational status and operating conditions";
CM_ BO_ 2155937824  "The setpoints control the behaviour of the DC Port of the AC01. The AC01 operates this port in CVCC mode";
CM_ BO_ 2155937825  "The setpoints that are currently used by the AC01. This message allows to validate that the setpoints have been properly applied.";
CM_ BO_ 2155937828  "Measurements of the DC Bus";
CM_ BO_ 2155937826  "Setpoints for applying Droop on the DC Port. Droop is needed for paralleling multiple AC01";
CM_ BO_ 2155937827  "Droop setpoints that are applied by the AC01";
CM_ BO_ 2155937842  "Mesured values of the Grid connection";
CM_ BO_ 2155937843  "Measurements for L1 of the AC port";
CM_ BO_ 2155937844  "Measurements for L2 of the AC port";
CM_ BO_ 2155937845  "Measurements for L3 of the AC port";
CM_ BO_ 2155937840  "Setpoints to apply to the AC Port";
CM_ BO_ 2155937841  "Setpoints that are currently being applied to the the AC Port";
CM_ BO_ 2155937792  "Identification of the device";
CM_ BO_ 2155937794  "Unique Identifier of the Firmware used on this device";
CM_ BO_ 2155937793  "Unique Identifier of the Bootloader used on this device";
CM_ BO_ 2155937795  "This message declares the version of the API that is provided by the device. The version follows newer convention, as this file is an API definition, patch does not apply";
CM_ BO_ 2155937861  "Device stack control";
CM_ BO_ 2155937872  "Fault Control: actions to clear faults and reset the system";
CM_ BO_ 2155937889  "FACTORY USE ONLY - Control the device factory flags";
CM_ BO_ 2155937810  "Converter control command";
CM_ BO_ 2155937811  "Real-time power converter performance metrics

                  Some signals are still experimental and may change in the future.
            ";
CM_ BO_ 2155937808  "General Status of the power converter";
CM_ BO_ 2155938032  "FSM  status - DEBUG ONLY, not for customer visibility";
CM_ BO_ 2155937809  "Fault status bitfield (1-bit flags per fault type)

                    Severity levels and clearing:
                    - Tripped: Can be cleared using \"Clear_Interlock\" signals from \"Fault_Control\" message.
                    - Critical: Requires system reboot (contact Advantics support).
                    - Error: Can be cleared using \"Clear_Interlock\" signals from \"Fault_Control\" message.

                    State machine behavior:
                    - Standby: All errors must be cleared before power-on is allowed. if \"Enable\"  is active, the converter will 
                      turns on when all faults/warnings are cleared.
                    - Running: Any Error fault triggers the turning-off sequence shutdown. And any Critical fault trigger immediate shutdown
                
            ";
CM_ BO_ 2155937813  "interface status";
CM_ BO_ 2155937814  "Configure the Heartbeat for the Module. The 'Heartbeat Period' signal only apply if the heartbeat signals are enabled";
CM_ BO_ 2155937815  "Readouts of the power converter temperature sensors";
CM_ BO_ 2155937816  "Readouts from the power converter's internal fans.";
CM_ BO_ 2155937817  "keep alive feeding";
CM_ BO_ 2155938033  "INTERNAL DEBUG ONLY - Customer systems should NOT monitor or display this message
                    
                    Split power converter interlock status
            ";
CM_ BO_ 2155937812  "Configure the broadcast group that the power converter belongs to.";
CM_ BO_ 2155937920  "DEBUG/FACTORY USE ONLY - Not important for customers. 
                
                    Contains information about the ADM-CS (controller).
            ";
CM_ BO_ 2155937921  "DEBUG/FACTORY USE ONLY - Not important for customers. 
                
                    Contains information about detected ADM-PC.
            ";
CM_ BO_ 2155937922  "DEBUG/FACTORY USE ONLY - Not important for customers. 
                
                    Contains information about detected ADM-PC #1.
            ";
CM_ BO_ 2155937923  "DEBUG/FACTORY USE ONLY - Not important for customers. 
                
                    Contains information about detected ADM-PC #2.
            ";
CM_ BO_ 2155937924  "DEBUG/FACTORY USE ONLY - Not important for customers. 
                
                    Contains information about detected ADM-PC #3.
            ";
CM_ BO_ 2155937925  "DEBUG/FACTORY USE ONLY - Not important for customers. 
                
                    Contains information about detected ADM-PC #4.
            ";
CM_ BO_ 2155937926  "DEBUG/FACTORY USE ONLY - Not important for customers. 
                
                    Contains information about detected ADM-PC #5.
            ";
CM_ BO_ 2155937927  "DEBUG/FACTORY USE ONLY - Not important for customers. 
                
                    Contains information about detected ADM-PC #6.
            ";
CM_ BO_ 2155937928  "DEBUG/FACTORY USE ONLY - Not important for customers. 
                
                    Contains status information about detected ADM-PC #1.
            ";
CM_ BO_ 2155937929  "DEBUG/FACTORY USE ONLY - Not important for customers. 
                
                    Contains status information about detected ADM-PC #2.
            ";
CM_ BO_ 2155937930  "DEBUG/FACTORY USE ONLY - Not important for customers. 
                
                    Contains status information about detected ADM-PC #3.
            ";
CM_ BO_ 2155937931  "DEBUG/FACTORY USE ONLY - Not important for customers. 
                
                    Contains status information about detected ADM-PC #4.
            ";
CM_ BO_ 2155937932  "DEBUG/FACTORY USE ONLY - Not important for customers. 
                
                    Contains status information about detected ADM-PC #5.
            ";
CM_ BO_ 2155937933  "DEBUG/FACTORY USE ONLY - Not important for customers. 
                
                    Contains status information about detected ADM-PC #6.
            ";
CM_ BO_ 2155937936  "Performance status of the AMD-CS";
CM_ BO_ 2155937937  "DEBUG - Allow to know  what ADM-PC has wrong can api";
CM_ BO_ 2155937890  "FACTORY USE ONLY - Calibration control (requires factory mode)

                    Should only be used in factory, not customers. For calibration issues, contact Advantics support.

            ";
CM_ BO_ 2155937891  "FACTORY USE ONLY - Calibration reading cmd (requires factory mode)

                Should only be used in factory, not customers. For calibration issues, contact Advantics support.";
CM_ BO_ 2155937892  "FACTORY USE ONLY - Calibration reading (requires factory mode)

                Should only be used in factory, not customers. For calibration issues, contact Advantics support";
CM_ BO_ 2155937888  "FACTORY USE ONLY - Factory configuration (requires factory mode)

                    Should only be used in factory, not customers. In case of issues, contact Advantics support.
            ";
CM_ BO_ 2155937893  "FACTORY USE ONLY - Factory debug command (requires factory mode)

                    Should only be used in factory, not customers. In case of issues, contact Advantics support.
            ";

CM_ SG_ 2155937856 mode "Requested operating mode

            DC_Controlled (0): DC side voltage controlled to setpoint, requires AC side input present
            AC_Controlled (1): AC side voltage controlled (not yet supported)
            Bleeding (2): Discharge internal capacitors/remaining charge

            changing mode can only be done when the power converter is not \"Enable\"";
CM_ SG_ 2155937857 mode "Currently applied operating mode

                changing mode can only be done when the power converter is not \"Enable\"
          ";
CM_ SG_ 2155937858 CABLE_1_2_L1 "Critical: Phase mismatch between DMF1(1).L1 and BP25(2).U";
CM_ SG_ 2155937858 CABLE_1_3_L1 "Critical: Phase mismatch between DMF1(1).L1 and BP25(3).U";
CM_ SG_ 2155937858 CABLE_1_2_L2 "Critical: Phase mismatch between DMF1(1).L2 and BP25(2).V";
CM_ SG_ 2155937858 CABLE_1_3_L2 "Critical: Phase mismatch between DMF1(1).L2 and BP25(3).V";
CM_ SG_ 2155937858 CABLE_1_2_L3 "Critical: Phase mismatch between DMF1(1).L3 and BP25(2).W";
CM_ SG_ 2155937858 CABLE_1_3_L3 "Critical: Phase mismatch between DMF1(1).L3 and BP25(3).W";
CM_ SG_ 2155937858 CABLE_4_5_L1 "Critical: Phase mismatch between DMF1(4).L1 and BP25(5).U";
CM_ SG_ 2155937858 CABLE_4_6_L1 "Critical: Phase mismatch between DMF1(4).L1 and BP25(6).U";
CM_ SG_ 2155937858 CABLE_4_5_L2 "Critical: Phase mismatch between DMF1(4).L2 and BP25(5).V";
CM_ SG_ 2155937858 CABLE_4_6_L2 "Critical: Phase mismatch between DMF1(4).L2 and BP25(6).V";
CM_ SG_ 2155937858 CABLE_4_5_L3 "Critical: Phase mismatch between DMF1(4).L3 and BP25(5).W";
CM_ SG_ 2155937858 CABLE_4_6_L3 "Critical: Phase mismatch between DMF1(4).L3 and BP25(6).W";
CM_ SG_ 2155937858 CABLE_1_4_L1 "Critical: Grid L1 mismatch between DMF1(1).IN and DMF1(4).IN";
CM_ SG_ 2155937858 CABLE_1_4_L2 "Critical: Phase mismatch between DMF1(1).L2 and DMF1(4).L2";
CM_ SG_ 2155937858 CABLE_1_4_L3 "Critical: Phase mismatch between DMF1(1).L3 and DMF1(4).L3";
CM_ SG_ 2155937858 CABLE_2_3_DC "Critical: DC mismatch between BP25(2) and BP25(3)";
CM_ SG_ 2155937858 CABLE_5_6_DC "Critical: DC mismatch between BP25(5) and BP25(6)";
CM_ SG_ 2155937858 CABLE_3_5_DC "Critical: DC mismatch between BP25(3) and BP25(5)";
CM_ SG_ 2155937858 MODULE_1_RUNNING "Error: Module 1 is running, but it should be off";
CM_ SG_ 2155937858 MODULE_2_RUNNING "Error: Module 2 is running, but it should be off";
CM_ SG_ 2155937858 MODULE_3_RUNNING "Error: Module 3 is running, but it should be off";
CM_ SG_ 2155937858 MODULE_4_RUNNING "Error: Module 4 is running, but it should be off";
CM_ SG_ 2155937858 MODULE_5_RUNNING "Error: Module 5 is running, but it should be off";
CM_ SG_ 2155937858 MODULE_6_RUNNING "Error: Module 6 is running, but it should be off";
CM_ SG_ 2155937858 reserved_1 "reserved_1";
CM_ SG_ 2155937858 reserved_2 "reserved_2";
CM_ SG_ 2155937858 reserved_3 "reserved_3";
CM_ SG_ 2155937858 reserved_4 "reserved_4";
CM_ SG_ 2155937858 PRECHARGE_FAILED "Error: Precharge failed";
CM_ SG_ 2155937858 Main_Contactors_failed "Error: Main contactors did not closed";
CM_ SG_ 2155937858 FILTER_NOT_RUNNING "Error: Filter is not running, but it should be active";
CM_ SG_ 2155937858 RECTIFIER_3P_NOT_RUNNING "Error: Three-phase rectifier is not running, but it should be active";
CM_ SG_ 2155937858 AFE_NOT_OFF "Error: AFE is not off, but it should be off";
CM_ SG_ 2155937858 FILTER_STOP_RUNNING "Error: Filter stop running";
CM_ SG_ 2155937858 RECTIFIER_3P_STOP_RUNNING "Error: Rectifier stop running";
CM_ SG_ 2155937858 AFE_PWM_NOT_RUNNING "Error: BLEEDING is not running";
CM_ SG_ 2155937858 AFE_PWM_STOP_RUNNING "Error: Bleeding stop running";
CM_ SG_ 2155937858 BLEEDING_FAILED "Error: Bleeding process failed";
CM_ SG_ 2155937858 FILTER_NOT_OFF "Error: Filter is not off, but it should be off";
CM_ SG_ 2155937858 INVERTER_3P_NOT_RUNNING "Error: Three-phase inverter is not running, but it should be active";
CM_ SG_ 2155937858 INVERTER_3P_STOP_RUNNING "Error: Three-phase inverter stop running";
CM_ SG_ 2155937859 grid_not_supported "Warning: Grid is not supported 

      
          3-Phase 230V (line-to-neutral) / 400V (line-to-line), 50Hz
          3-Phase 277V (line-to-neutral) / 480V (line-to-line), 60Hz
          3-Phase 120V (line-to-neutral) / 208V (line-to-line), 60Hz
      ";
CM_ SG_ 2155937859 grid_not_existing "Warning: The converter is not connected to existing grid ";
CM_ SG_ 2155937859 grid_selection_wrong "Warning: grid selection is wrong

            converter see an existing grid and the selected grid mode is different 
      ";
CM_ SG_ 2155937859 reserved_3 "reserved";
CM_ SG_ 2155937859 V_SET_DC_BELOW_AC "Warning: DC voltage setpoint is lower than the measured AC voltage

              It needs to follow this equation::
                    Vset DC > VAC rms * sqrt(2) * 2 + 20
      ";
CM_ SG_ 2155937859 V_DC_BELOW_AC "Warning: DC voltage measured is too low to generate AC voltage

              It needs to follow this equation::
                    Vset DC > VAC rms * sqrt(2) * 2 + 20
      ";
CM_ SG_ 2155937859 AFE_DROOP_NOT_ENABLE "Warning: AFE droop control is disabled but expected to be enabled";
CM_ SG_ 2155937859 MODE_NOT_SUPPORTED "Warning: The selected operating mode is not supported";
CM_ SG_ 2155937859 V_A_LOW "Warning: Port A voltage is below the minimum operating threshold";
CM_ SG_ 2155937859 V_A_HIGH "Warning: Port A voltage exceeds the maximum operating threshold";
CM_ SG_ 2155937859 V_B_LOW "Warning: Port A voltage is below the minimum operating threshold";
CM_ SG_ 2155937859 V_B_HIGH "Warning: Port A voltage exceeds the maximum operating threshold";
CM_ SG_ 2155937860 BLEEDING_DONE "Info: Bleeding process completed successfully";
CM_ SG_ 2155937860 CURRENT_LIMIT "Info: Current limit has been reached";
CM_ SG_ 2155937860 CURRENT_LIMITED_BY_POWER "Info: Output current is limited because the maximum power is reached";
CM_ SG_ 2155937860 VB_LIMITED_BY_VA "Info: Output voltage VB is limited because input voltage VA is insufficient";
CM_ SG_ 2155937824 Voltage "Control the target dc side voltage. This voltage will be maintained as long as the current required to do so is smaller than the current limits specified in this message";
CM_ SG_ 2155937824 Positive_Current_Limit "The maximum current that the AC01 will source on the DC Port";
CM_ SG_ 2155937824 Negative_Current_Limit "The maximum current that the AC01 will sink into the DC Port";
CM_ SG_ 2155937825 Voltage "The voltage target of the DC port";
CM_ SG_ 2155937825 Positive_Current_Limit "The maximum current that the AC01 will source on the DC Port";
CM_ SG_ 2155937825 Negative_Current_Limit "The maximum amount of current that the AC01 will sink into the DC port";
CM_ SG_ 2155937828 Voltage "Voltage on the DC Port";
CM_ SG_ 2155937828 Current "Current through the DC Port";
CM_ SG_ 2155937826 Positive_Current_Droop "The droop resistance to apply for current flowing out of the DC port (DC current is positive)";
CM_ SG_ 2155937826 Negative_Current_Droop "The droop resistance to apply for current flowing in to the DC Port (DC current is negative)";
CM_ SG_ 2155937826 Enable "Enable DC Droop. If this feature is enabled the output voltage of the DC port varies with output current.";
CM_ SG_ 2155937826 Reserved "This space is reserved. This region should contain only '0's";
CM_ SG_ 2155937827 Positive_Current_Droop "The droop resistance applied for current flowing out of the DC port (DC current is positive)";
CM_ SG_ 2155937827 Negative_Current_Droop "The droop resistance applied for current flowing in to the DC Port (DC current is negative)";
CM_ SG_ 2155937827 Enable "Show is DC Droop is enabled.";
CM_ SG_ 2155937827 Reserved "This space is reserved. This region should contain only '0's";
CM_ SG_ 2155937842 Frequency "RMS Voltage of L1";
CM_ SG_ 2155937842 Voltage "Average RMS Line to Line voltage at the AC port";
CM_ SG_ 2155937842 Reserved "This space is reserved. This region contains only '0's";
CM_ SG_ 2155937843 U "RMS Voltage of L1";
CM_ SG_ 2155937843 I "RMS Current of L1";
CM_ SG_ 2155937843 P "Active power of L1";
CM_ SG_ 2155937843 Q "Reactive power of L1";
CM_ SG_ 2155937844 U "RMS Voltage of L1";
CM_ SG_ 2155937844 I "RMS Current of L2";
CM_ SG_ 2155937844 P "Active power of L2";
CM_ SG_ 2155937844 Q "Reactive power of L2";
CM_ SG_ 2155937845 U "RMS Voltage of L3";
CM_ SG_ 2155937845 I "RMS Current of L3";
CM_ SG_ 2155937845 P "Active power of L3";
CM_ SG_ 2155937845 Q "Reactive power of L3";
CM_ SG_ 2155937840 grid "select grid type that should be generated. All grids are 3-phase.

                FOLLOWING (0): Follows existing grid if compatible (see below).
                230V_400V_50HZ (1): 3-Phase 230V (line-to-neutral) / 400V (line-to-line), 50Hz
                277V_480V_60HZ (2): 3-Phase 277V (line-to-neutral) / 480V (line-to-line), 60Hz
                120V_208V_60HZ (3): 3-Phase 120V (line-to-neutral) / 208V (line-to-line), 60Hz
        ";
CM_ SG_ 2155937840 Q "Reactive Power of the AC port. Positive values cause the AC01 to behave inductively, negative values cause the AC01 to behave capacitively";
CM_ SG_ 2155937840 RMS_Phase_Current_Limit "The maximum RMS current that the AC01 will supply at its AC terminals.
                This value limits the the magnitute of the AC current and applies
                symmetrically to both source and sink currents. This limit applies to
                the current carried by a single phase.
        ";
CM_ SG_ 2155937841 grid "select grid type that should be generated. All grids are 3-phase.
                        
                FOLLOWING (0): Follows existing grid if compatible (see below).
                230V_400V_50HZ (1): 3-Phase 230V (line-to-neutral) / 400V (line-to-line), 50Hz
                277V_480V_60HZ (2): 3-Phase 277V (line-to-neutral) / 480V (line-to-line), 60Hz
                120V_208V_60HZ (3): 3-Phase 120V (line-to-neutral) / 208V (line-to-line), 60Hz
        ";
CM_ SG_ 2155937841 Q "Reactive Power of the AC port. Positive values cause the AC01 to behave inductively, negative values cause the AC01 to behave capacitively";
CM_ SG_ 2155937841 RMS_Phase_Current_Limit "The maximum RMS current that the AC01 will supply at its AC terminals.
                This value limits the the magnitute of the AC current and applies
                symmetrically to both source and sink currents. This limit applies to
                the current carried by a single phase.
        ";
CM_ SG_ 2155937792 Type "Type of device";
CM_ SG_ 2155937792 Revision "The hardware revision number";
CM_ SG_ 2155937792 Variant "The hardware variant";
CM_ SG_ 2155937792 Stack_position "Position of the device within the stack";
CM_ SG_ 2155937792 serial_number "Unique device serial number";
CM_ SG_ 2155937795 Major "The Major version number. This number increases if there are backwards incompatible changes";
CM_ SG_ 2155937795 Minor "The Minor version number. This number increases if there are backwards compatible changes, like new messages or the use of previously reserved space";
CM_ SG_ 2155937795 Patch "The Patch number. This number increases when changes to descriptions and documentation/comments are made";
CM_ SG_ 2155937861 Stack_position "Device position within the stack";
CM_ SG_ 2155937861 reserved "reserved";
CM_ SG_ 2155937861 SN_number "Unique device serial number, that require change of stack address";
CM_ SG_ 2155937872 Clear_Interlock "Clears the device interlock";
CM_ SG_ 2155937872 Reset_Processor "Reset the device DSP";
CM_ SG_ 2155937872 Trip_Interlock "Trip the internal Interlock";
CM_ SG_ 2155937872 Reserved "Reserved";
CM_ SG_ 2155937889 Factory_mode "If set to 1, module will enter in factory mode. ";
CM_ SG_ 2155937810 enable "Enable the power converter 
                       enable takes priority over sleep
                ";
CM_ SG_ 2155937810 sleep "Ask the converter to go to sleep mode 

                        the converter will go to sleep mode only from standby mode
                        enable  takes priority over sleep
                ";
CM_ SG_ 2155937811 load "Current load utilization 
                        
                    Actual power demand relative to Power_capability limit.
                ";
CM_ SG_ 2155937811 efficiency "Converter efficiency";
CM_ SG_ 2155937811 Power_capability " Maximum deliverable power based on configured setpoints (V * A).
             
                    Examples:
                        - 1000V * 50A = 50kW  (within limits)
                        - 1500V * 200A = 300kW  capped at 100kW (converter maximum)
                ";
CM_ SG_ 2155937811 low_power_input "low-voltage input (typically 24V)";
CM_ SG_ 2155937808 State "Current operating state of the power converter.

                        Init: The converter is initializing. It will transition to Standby if initialization succeeds, 
                        or to Critical/Error if it fails.
                        Standby: The converter is idle and ready to be turned-on if conditions are met (no errors, no warnings).
                        Turning_on: The converter is powering up.
                        Running: The converter is actively operating.
                        Turning_off: The converter is shutting down.
                        Error: A recoverable fault has occurred.
                        Critical: A critical fault has occurred, requiring reboot (please inform Advantics).
                        God: For Developer (mode cannot be used by customers).
                        Sleeping: The converter is in sleeping mode in order to save energy.
                ";
CM_ SG_ 2155937808 flag_enable "Indicates  that the converter is asked to be enabled.
                        once condition are meet (no wanring nor error) the converter will do to turning-on
                ";
CM_ SG_ 2155937808 flag_ready "Indicates that a valid setpoint has been received and conditions are met to turn on the converter.";
CM_ SG_ 2155937808 flag_energized "Indicates that the converter is energized (internal and external > 24V)";
CM_ SG_ 2155937808 flag_busy "Indicates that the converter is in a transition state (init, turning on, or turning off). Some commands may be ignored during this step.";
CM_ SG_ 2155937808 flag_sleep "Indicates that the converter is asked to operating in energy-saving (sleep) mode.

                        the converter will go in sleeping mode
                        Turning on the power converter in eco mode may take a little more time (feature not yet implemented).
                ";
CM_ SG_ 2155937808 flag_warning "Indicates that one or more warnings are active.

                        When in standby mode, all warnings must be cleared before turning on the power converter.
                        If \"Enable\" is set in \"Converter_Control\", the power converter will turn on as soon as all warnings are cleared.
                        The system may be operating in degraded mode.
                        During operation (Running), the power converter will continue to run, but degraded performance may be expected.
                        Refer to the \"Warning\" message for more details.
                ";
CM_ SG_ 2155937808 flag_degraded "Indicates that the converter is running in degraded performance mode 

                    This can be due to high temperature.
                    Refer to the \"Warning\" message for more details.

                ";
CM_ SG_ 2155937808 flag_error "Indicates that one or more Errors are active.

                    When in standby mode, all errors must be cleared before turning on the power converter.
                    If \"Enable\" is set in \"Converter_Control\", the power converter will turn on as soon as all warnings are cleared.
                    During operation (Running), the power converter will turn off.
                    Errors can be cleared using \"Clear_Interlock\" signals from the \"Fault_Control\" message.
                    The system may be operating in degraded mode.
                    Refer to the \"Errors\" or \"Faults\" message for more details.
                ";
CM_ SG_ 2155937808 flag_factory "Indicates that the converter is operating in factory or service mode. 

                        This flag should not be active for customers
                ";
CM_ SG_ 2155937808 flag_god_mode "Indicates that the converter is in special diagnostic or unrestricted mode (god mode).
                    
                        This flag should not be active for customers

                ";
CM_ SG_ 2155938032 init "state: INIT (initialization phase)";
CM_ SG_ 2155938032 ready "state: READY ";
CM_ SG_ 2155938032 turned_on "state: TURNED_ON";
CM_ SG_ 2155938032 turned_off "state: TURNED_OFF";
CM_ SG_ 2155938032 bleeding "state: BLEEDING";
CM_ SG_ 2155937809 internal "Internal interlock trip 
                    
                    An internal issue has arisen.
                ";
CM_ SG_ 2155937809 external "External interlock trip

                    Common causes:
                    - External emergency stop button pressed
                    - External safety interlock opened (door switch, guard, etc.)
                ";
CM_ SG_ 2155937809 system "Critical system fault detected (contact Advantics support)";
CM_ SG_ 2155937809 EEPROM_failure "EEPROM read/write failure (contact Advantics support)";
CM_ SG_ 2155937809 wrong_nfo "Invalid configuration detected (contact Advantics support)";
CM_ SG_ 2155937809 Measurement_system_failure "Voltage/current measurement system fault (contact Advantics support)";
CM_ SG_ 2155937809 PLL_not_locked "PLL not locked (contact Advantics support)";
CM_ SG_ 2155937809 overtemperature "Over-temperature condition detected 

                    Cooling plate temperature exceeded 75°C threshold
                    Can be cleared once temperature is bellow 75°C. check message \"Converter_Temperature\"

                ";
CM_ SG_ 2155937809 fan_stuck "Cooling fan stalled or not running

                        The system may overheat(contact Advantics support if the problem persist)
                ";
CM_ SG_ 2155937809 dead_module "Lost communication between the ADM-CS and one or more ADM-PC";
CM_ SG_ 2155937809 keep_alive_not_serv_internal "Internal ADM-PC keep-alive watchdog timeout. Was not served in time by ADM-CS";
CM_ SG_ 2155937809 error_temperature "Temperature sensor error. One or more sensors are unavailable or reporting invalid data.";
CM_ SG_ 2155937809 internal_modules_ready "One or more internal modules (ADM-PC) are NOT ready";
CM_ SG_ 2155937809 internal_modules_can_api "One or more internal modules (ADM-PC) have mismatched CAN API versions expected by ADM-CS
                        
                        check message \"info_can_api_error\" for more detail
                ";
CM_ SG_ 2155937809 internal_modules_missing "One or more internal modules (ADM-PC) are  missing (not detect on can bus)

                        check message \"info_adm_pc\" for more detail
                ";
CM_ SG_ 2155937809 internal_modules_wrong "One or more internal modules (ADM-PC) are not compatible with the NFO of ADM-CS";
CM_ SG_ 2155937809 internal_modules_stack "One or more internal modules (ADM-PC) don't respect the required stack position for the NFO of ADM-CS";
CM_ SG_ 2155937809 internal_modules_init "One or more internal modules (ADM-PC) failed at init (ready flag)";
CM_ SG_ 2155937809 wrong_revision "One or more internal modules (ADM-PC) don't have the required revision for the NFO of ADM-CS ";
CM_ SG_ 2155937809 v_in_low "24V input voltage too low

                        Increase voltage and/or current before clearing the error.
                ";
CM_ SG_ 2155937809 v_in_critical "24V input voltage critically low, 

                        Increase voltage and/or current and reboot the power converter
                ";
CM_ SG_ 2155937809 keep_alive_not_serv "keep-alive watchdog timeout

                    Upper controller did not service the keepalive watchdog in time.
                    Check \"Interface_Status\" message and increase \"keep_Alive_Period\" if needed
                ";
CM_ SG_ 2155937813 Broadcast_Group "The broadcast group that the module belongs to. Broadcast group 0 implies that the module is not part of a broadcast group. ";
CM_ SG_ 2155937813 keep_Alive "keep alive requires the supervisory/upper controller to send a heartbeat message at regular intervals";
CM_ SG_ 2155937813 reserved "reserved for future usage";
CM_ SG_ 2155937813 keep_Alive_Period "The maximum period of the keep alive message. If the time between two heart-beat messages is longer than this value, the power converter will go to Error. This only applies when the Heartbeat signal is Enabled";
CM_ SG_ 2155937814 Enable "Enable/Disable the Heartbeat feature of the Module";
CM_ SG_ 2155937814 reserved "Reserved for future usage";
CM_ SG_ 2155937814 Period "Set the maximum period of the Heartbeat message. If the time between two heart-beat messages is longer than this value, the power converter will go to Error.";
CM_ SG_ 2155937815 Cooling_plate "Temperature of the cooling plate";
CM_ SG_ 2155937815 Magnetics "Highest measured temp of magnetics";
CM_ SG_ 2155937815 Transistors "Highest measured temp of transistors";
CM_ SG_ 2155937815 reserved "reserved for future usage";
CM_ SG_ 2155937816 A_rpm "Measured speed of Fan A";
CM_ SG_ 2155937816 A_pwm "Fan A target speed in percentage (0 to 100%)";
CM_ SG_ 2155937816 B_rpm "Measured speed of Fan B";
CM_ SG_ 2155937816 B_pwm "Fan B target speed in percentage (0 to 100%)";
CM_ SG_ 2155937817 feed "The value doesn't matter here, it is only used to feed the keepalive";
CM_ SG_ 2155937812 Group_ID "Broadcast Group that the power converter should monitor";
CM_ SG_ 2155937920 Type "The device identification field";
CM_ SG_ 2155937920 Revision "The hardware revision numbere";
CM_ SG_ 2155937920 Variant "Hardware variant";
CM_ SG_ 2155937920 reserved "Hardware variant";
CM_ SG_ 2155937920 serial_number "Hardware variant";
CM_ SG_ 2155937921 nb_detected "number of ADM-PC detected";
CM_ SG_ 2155937921 nd_side_a "number of ADM-PC detected";
CM_ SG_ 2155937921 nd_side_b "number of ADM-PC detected";
CM_ SG_ 2155937921 Collision "collision between module";
CM_ SG_ 2155937922 Type "The device identification field";
CM_ SG_ 2155937922 Revision "The hardware revision number";
CM_ SG_ 2155937922 Variant "Hardware variant";
CM_ SG_ 2155937922 Stack_position "Hardware variant";
CM_ SG_ 2155937922 serial_number "Hardware variant";
CM_ SG_ 2155937923 Type "The device identification field";
CM_ SG_ 2155937923 Revision "The hardware revision number";
CM_ SG_ 2155937923 Variant "Hardware variant";
CM_ SG_ 2155937923 Stack_position "Hardware variant";
CM_ SG_ 2155937923 serial_number "Hardware variant";
CM_ SG_ 2155937924 Type "The device identification field";
CM_ SG_ 2155937924 Revision "The hardware revision number";
CM_ SG_ 2155937924 Variant "Hardware variant";
CM_ SG_ 2155937924 Stack_position "Hardware variant";
CM_ SG_ 2155937924 serial_number "Hardware variant";
CM_ SG_ 2155937925 Type "The device identification field";
CM_ SG_ 2155937925 Revision "The hardware revision number";
CM_ SG_ 2155937925 Variant "Hardware variant";
CM_ SG_ 2155937925 Stack_position "Hardware variant";
CM_ SG_ 2155937925 serial_number "Hardware variant";
CM_ SG_ 2155937926 Type "The device identification field";
CM_ SG_ 2155937926 Revision "The hardware revision number";
CM_ SG_ 2155937926 Variant "Hardware variant";
CM_ SG_ 2155937926 Stack_position "Hardware variant";
CM_ SG_ 2155937926 serial_number "Hardware variant";
CM_ SG_ 2155937927 Type "The device identification field";
CM_ SG_ 2155937927 Revision "The hardware revision number";
CM_ SG_ 2155937927 Variant "Hardware variant";
CM_ SG_ 2155937927 Stack_position "Hardware variant";
CM_ SG_ 2155937927 serial_number "Hardware variant";
CM_ SG_ 2155937928 Available "The device available";
CM_ SG_ 2155937928 Side "The device is Ready";
CM_ SG_ 2155937928 Status "The device is Running";
CM_ SG_ 2155937928 Interlock_I "The device have interlock internal";
CM_ SG_ 2155937928 Interlock_E "The device have interlock external";
CM_ SG_ 2155937928 mode "Mode";
CM_ SG_ 2155937929 Available "The device available";
CM_ SG_ 2155937929 Side "The device is Ready";
CM_ SG_ 2155937929 Status "The device is Running";
CM_ SG_ 2155937929 Interlock_I "The device have interlock internal";
CM_ SG_ 2155937929 Interlock_E "The device have interlock external";
CM_ SG_ 2155937929 mode "Mode";
CM_ SG_ 2155937930 Available "The device available";
CM_ SG_ 2155937930 Side "The device is Ready";
CM_ SG_ 2155937930 Status "The device is Running";
CM_ SG_ 2155937930 Interlock_I "The device have interlock internal";
CM_ SG_ 2155937930 Interlock_E "The device have interlock external";
CM_ SG_ 2155937930 mode "Mode";
CM_ SG_ 2155937931 Available "The device available";
CM_ SG_ 2155937931 Side "The device is Ready";
CM_ SG_ 2155937931 Status "The device is Running";
CM_ SG_ 2155937931 Interlock_I "The device have interlock internal";
CM_ SG_ 2155937931 Interlock_E "The device have interlock external";
CM_ SG_ 2155937931 mode "Mode";
CM_ SG_ 2155937932 Available "The device available";
CM_ SG_ 2155937932 Side "The device is Ready";
CM_ SG_ 2155937932 Status "The device is Running";
CM_ SG_ 2155937932 Interlock_I "The device have interlock internal";
CM_ SG_ 2155937932 Interlock_E "The device have interlock external";
CM_ SG_ 2155937932 mode "Mode";
CM_ SG_ 2155937933 Available "The device available";
CM_ SG_ 2155937933 Side "The device is Ready";
CM_ SG_ 2155937933 Status "The device is Running";
CM_ SG_ 2155937933 Interlock_I "The device have interlock internal";
CM_ SG_ 2155937933 Interlock_E "The device have interlock external";
CM_ SG_ 2155937933 mode "Mode";
CM_ SG_ 2155937936 cpu_1_usage "Controller cpu 1 usage";
CM_ SG_ 2155937936 cpu_2_usage "Controller cpu 2 usage";
CM_ SG_ 2155937936 can_bus_load_A "Controller cup 1 usage";
CM_ SG_ 2155937936 can_bus_load_B "Controller cpu 1 usage";
CM_ SG_ 2155937936 main_loop_freq "Controller cpu 1 usage";
CM_ SG_ 2155937937 Type "The ADM-PC identification field";
CM_ SG_ 2155937937 Stack_position "Hardware variant";
CM_ SG_ 2155937937 Major_expected "The Major version number. This number increases if there are backwards incompatible changes";
CM_ SG_ 2155937937 Minor_expected "The minor version number. This number increases if there are backwards incompatible changes";
CM_ SG_ 2155937937 Patch_expected "The patch version number. This number increases if there are backwards incompatible changes";
CM_ SG_ 2155937937 Major_actual "The Major version number. This number increases if there are backwards incompatible changes";
CM_ SG_ 2155937937 Minor_actual "The minor version number. This number increases if there are backwards incompatible changes";
CM_ SG_ 2155937937 Patch_actual "The patch version number. This number increases if there are backwards incompatible changes";
CM_ SG_ 2155937890 index "index of the device that nee calibration (0 is invalid) ";
CM_ SG_ 2155937890 select "select what value to set";
CM_ SG_ 2155937890 value "require calibration value ";
CM_ SG_ 2155937891 index "index of the device that need reading ";
CM_ SG_ 2155937891 select "select what value to read";
CM_ SG_ 2155937892 index "index of the device that need reading ";
CM_ SG_ 2155937892 select "select what value to read";
CM_ SG_ 2155937892 calibration_status "select what value to read";
CM_ SG_ 2155937892 reserved "select what value to read";
CM_ SG_ 2155937892 value "require calibration valut ";
CM_ SG_ 2155937888 select "set ID (will apply setted revision and variant as well)";
CM_ SG_ 2155937888 set_id "set ID, need factory mode = 1 (will change revision and variant as well)";
CM_ SG_ 2155937888 set_revision "set revision, need factory mode = 1 , applied if set_id is valid";
CM_ SG_ 2155937888 set_variant "set variant, need factory mode = 1, applied if set_id is valid";
CM_ SG_ 2155937893 god_mode "If set to 1, module will enter in god mode. ";
CM_ SG_ 2155937893 internal_power_a "If set to 1, ADM-PC on side A will be turned off";
CM_ SG_ 2155937893 internal_power_b "If set to 1, ADM-PC on side B will be turned off";
CM_ SG_ 2155937893 offset_stack_internal "Allow to generate a virtual offset in the stack address for internal ADM-PC";

VAL_ 2155937856 mode 0 "DC_Controlled" 1 "AC_Controlled" 2 "Bleeding";
VAL_ 2155937857 mode 0 "DC_Controlled" 1 "AC_Controlled" 2 "Bleeding";
VAL_ 2155937858 CABLE_1_2_L1 0 "Clear" 1 "Critical";
VAL_ 2155937858 CABLE_1_3_L1 0 "Clear" 1 "Critical";
VAL_ 2155937858 CABLE_1_2_L2 0 "Clear" 1 "Critical";
VAL_ 2155937858 CABLE_1_3_L2 0 "Clear" 1 "Critical";
VAL_ 2155937858 CABLE_1_2_L3 0 "Clear" 1 "Critical";
VAL_ 2155937858 CABLE_1_3_L3 0 "Clear" 1 "Critical";
VAL_ 2155937858 CABLE_4_5_L1 0 "Clear" 1 "Critical";
VAL_ 2155937858 CABLE_4_6_L1 0 "Clear" 1 "Critical";
VAL_ 2155937858 CABLE_4_5_L2 0 "Clear" 1 "Critical";
VAL_ 2155937858 CABLE_4_6_L2 0 "Clear" 1 "Critical";
VAL_ 2155937858 CABLE_4_5_L3 0 "Clear" 1 "Critical";
VAL_ 2155937858 CABLE_4_6_L3 0 "Clear" 1 "Critical";
VAL_ 2155937858 CABLE_1_4_L1 0 "Clear" 1 "Critical";
VAL_ 2155937858 CABLE_1_4_L2 0 "Clear" 1 "Critical";
VAL_ 2155937858 CABLE_1_4_L3 0 "Clear" 1 "Critical";
VAL_ 2155937858 CABLE_2_3_DC 0 "Clear" 1 "Critical";
VAL_ 2155937858 CABLE_5_6_DC 0 "Clear" 1 "Critical";
VAL_ 2155937858 CABLE_3_5_DC 0 "Clear" 1 "Critical";
VAL_ 2155937858 MODULE_1_RUNNING 0 "Clear" 1 "Error";
VAL_ 2155937858 MODULE_2_RUNNING 0 "Clear" 1 "Error";
VAL_ 2155937858 MODULE_3_RUNNING 0 "Clear" 1 "Error";
VAL_ 2155937858 MODULE_4_RUNNING 0 "Clear" 1 "Error";
VAL_ 2155937858 MODULE_5_RUNNING 0 "Clear" 1 "Error";
VAL_ 2155937858 MODULE_6_RUNNING 0 "Clear" 1 "Error";
VAL_ 2155937858 reserved_1 0 "Clear" 1 "Error";
VAL_ 2155937858 reserved_2 0 "Clear" 1 "Error";
VAL_ 2155937858 reserved_3 0 "Clear" 1 "Error";
VAL_ 2155937858 reserved_4 0 "Clear" 1 "Error";
VAL_ 2155937858 PRECHARGE_FAILED 0 "Clear" 1 "Error";
VAL_ 2155937858 Main_Contactors_failed 0 "Clear" 1 "Error";
VAL_ 2155937858 FILTER_NOT_RUNNING 0 "Clear" 1 "Error";
VAL_ 2155937858 RECTIFIER_3P_NOT_RUNNING 0 "Clear" 1 "Error";
VAL_ 2155937858 AFE_NOT_OFF 0 "Clear" 1 "Error";
VAL_ 2155937858 FILTER_STOP_RUNNING 0 "Clear" 1 "Error";
VAL_ 2155937858 RECTIFIER_3P_STOP_RUNNING 0 "Clear" 1 "Error";
VAL_ 2155937858 AFE_PWM_NOT_RUNNING 0 "Clear" 1 "Error";
VAL_ 2155937858 AFE_PWM_STOP_RUNNING 0 "Clear" 1 "Error";
VAL_ 2155937858 BLEEDING_FAILED 0 "Clear" 1 "Error";
VAL_ 2155937858 FILTER_NOT_OFF 0 "Clear" 1 "Error";
VAL_ 2155937858 INVERTER_3P_NOT_RUNNING 0 "Clear" 1 "Error";
VAL_ 2155937858 INVERTER_3P_STOP_RUNNING 0 "Clear" 1 "Error";
VAL_ 2155937859 grid_not_supported 0 "Clear" 1 "Warning";
VAL_ 2155937859 grid_not_existing 0 "Clear" 1 "Warning";
VAL_ 2155937859 grid_selection_wrong 0 "Clear" 1 "Warning";
VAL_ 2155937859 reserved_3 0 "Clear" 1 "Warning";
VAL_ 2155937859 V_SET_DC_BELOW_AC 0 "Clear" 1 "Warning";
VAL_ 2155937859 V_DC_BELOW_AC 0 "Clear" 1 "Warning";
VAL_ 2155937859 AFE_DROOP_NOT_ENABLE 0 "Clear" 1 "Warning";
VAL_ 2155937859 MODE_NOT_SUPPORTED 0 "Clear" 1 "Warning";
VAL_ 2155937859 V_A_LOW 0 "Clear" 1 "Warning";
VAL_ 2155937859 V_A_HIGH 0 "Clear" 1 "Warning";
VAL_ 2155937859 V_B_LOW 0 "Clear" 1 "Warning";
VAL_ 2155937859 V_B_HIGH 0 "Clear" 1 "Warning";
VAL_ 2155937860 BLEEDING_DONE 0 "Clear" 1 "Info";
VAL_ 2155937860 CURRENT_LIMIT 0 "Clear" 1 "Info";
VAL_ 2155937860 CURRENT_LIMITED_BY_POWER 0 "Clear" 1 "Info";
VAL_ 2155937860 VB_LIMITED_BY_VA 0 "Clear" 1 "Info";
VAL_ 2155937826 Enable 0 "Disabled" 1 "Enabled";
VAL_ 2155937827 Enable 0 "Disabled" 1 "Enabled";
VAL_ 2155937840 grid 0 "FOLLOWING" 1 "230V_400V_50HZ" 2 "277V_480V_60HZ" 3 "120V_208V_60HZ";
VAL_ 2155937841 grid 0 "FOLLOWING" 1 "230V_400V_50HZ" 2 "277V_480V_60HZ" 3 "120V_208V_60HZ";
VAL_ 2155937792 Type 128 "GC01" 129 "AC01" 130 "DC01";
VAL_ 2155937792 Revision 0 "R0A" 1 "R0B" 2 "R0C";
VAL_ 2155937792 Variant 0 "VA00" 1 "VA01";
VAL_ 2155937808 State 0 "init" 1 "standby" 2 "turning_on" 3 "running" 4 "turning_off" 5 "error" 6 "critical" 7 "god" 8 "sleeping";
VAL_ 2155937809 internal 0 "Clear" 1 "Tripped";
VAL_ 2155937809 external 0 "Clear" 1 "Tripped";
VAL_ 2155937809 system 0 "Clear" 1 "Critical";
VAL_ 2155937809 EEPROM_failure 0 "Clear" 1 "Critical";
VAL_ 2155937809 wrong_nfo 0 "Clear" 1 "Critical";
VAL_ 2155937809 Measurement_system_failure 0 "Clear" 1 "Warning";
VAL_ 2155937809 PLL_not_locked 0 "Clear" 1 "Critical";
VAL_ 2155937809 overtemperature 0 "Clear" 1 "Error";
VAL_ 2155937809 fan_stuck 0 "Clear" 1 "Warning";
VAL_ 2155937809 dead_module 0 "Clear" 1 "Error";
VAL_ 2155937809 keep_alive_not_serv_internal 0 "Clear" 1 "Error";
VAL_ 2155937809 error_temperature 0 "Clear" 1 "Info";
VAL_ 2155937809 internal_modules_ready 0 "Clear" 1 "Error";
VAL_ 2155937809 internal_modules_can_api 0 "Clear" 1 "Critical";
VAL_ 2155937809 internal_modules_missing 0 "Clear" 1 "Critical";
VAL_ 2155937809 internal_modules_wrong 0 "Clear" 1 "Critical";
VAL_ 2155937809 internal_modules_stack 0 "Clear" 1 "Critical";
VAL_ 2155937809 internal_modules_init 0 "Clear" 1 "Error";
VAL_ 2155937809 wrong_revision 0 "Clear" 1 "Critical";
VAL_ 2155937809 v_in_low 0 "Clear" 1 "Error";
VAL_ 2155937809 v_in_critical 0 "Clear" 1 "Critical";
VAL_ 2155937809 keep_alive_not_serv 0 "Clear" 1 "Error";
VAL_ 2155937813 keep_Alive 0 "Disabled" 1 "Enabled";
VAL_ 2155937813 reserved 0 "Disabled" 1 "Enabled";
VAL_ 2155937814 Enable 0 "Disabled" 1 "Enabled";
VAL_ 2155937814 reserved 0 "Disabled" 1 "Enabled";
VAL_ 2155938033 e 0 "Tripped" 1 "Clear";
VAL_ 2155938033 a 0 "Tripped" 1 "Clear";
VAL_ 2155938033 b 0 "Tripped" 1 "Clear";
VAL_ 2155938033 i 0 "Tripped" 1 "Clear";
VAL_ 2155938033 x 0 "Tripped" 1 "Clear";
VAL_ 2155937920 Type 16 "GC01";
VAL_ 2155937922 Type 7 "BP25" 8 "BI25" 19 "DMF1";
VAL_ 2155937923 Type 7 "BP25" 8 "BI25" 19 "DMF1";
VAL_ 2155937924 Type 7 "BP25" 8 "BI25" 19 "DMF1";
VAL_ 2155937925 Type 7 "BP25" 8 "BI25" 19 "DMF1";
VAL_ 2155937926 Type 7 "BP25" 8 "BI25" 19 "DMF1";
VAL_ 2155937927 Type 7 "BP25" 8 "BI25" 19 "DMF1";
VAL_ 2155937928 Side 0 "side_unk" 1 "side_a" 2 "side_b";
VAL_ 2155937928 Status 0 "off" 1 "ready" 2 "running";
VAL_ 2155937929 Side 0 "side_unk" 1 "side_a" 2 "side_b";
VAL_ 2155937929 Status 0 "off" 1 "ready" 2 "running";
VAL_ 2155937930 Side 0 "side_unk" 1 "side_a" 2 "side_b";
VAL_ 2155937930 Status 0 "off" 1 "ready" 2 "running";
VAL_ 2155937931 Side 0 "side_unk" 1 "side_a" 2 "side_b";
VAL_ 2155937931 Status 0 "off" 1 "ready" 2 "running";
VAL_ 2155937932 Side 0 "side_unk" 1 "side_a" 2 "side_b";
VAL_ 2155937932 Status 0 "off" 1 "ready" 2 "running";
VAL_ 2155937933 Side 0 "side_unk" 1 "side_a" 2 "side_b";
VAL_ 2155937933 Status 0 "off" 1 "ready" 2 "running";
VAL_ 2155937937 Type 7 "BP25" 8 "BI25" 19 "DMF1";
VAL_ 2155937890 index 0 "invalid" 1 "voltage_sensor_b";
VAL_ 2155937890 select 0 "invalid" 1 "prob_offset" 2 "prob_scale_factor";
VAL_ 2155937891 index 0 "invalid" 1 "voltage_sensor_b";
VAL_ 2155937891 select 0 "raw" 1 "value" 2 "prob_offset" 3 "prob_scale_factor";
VAL_ 2155937892 index 0 "unvalid" 1 "voltage_sensor_b";
VAL_ 2155937892 select 0 "raw" 1 "value" 2 "prob_offset" 3 "prob_scale_factor";
VAL_ 2155937892 calibration_status 0 "bad" 1 "ok";
VAL_ 2155937888 select 0 "invalid" 1 "cs" 2 "adb" 3 "reset";
VAL_ 2155937893 internal_power_a 0 "on" 1 "off";
VAL_ 2155937893 internal_power_b 0 "on" 1 "off";
